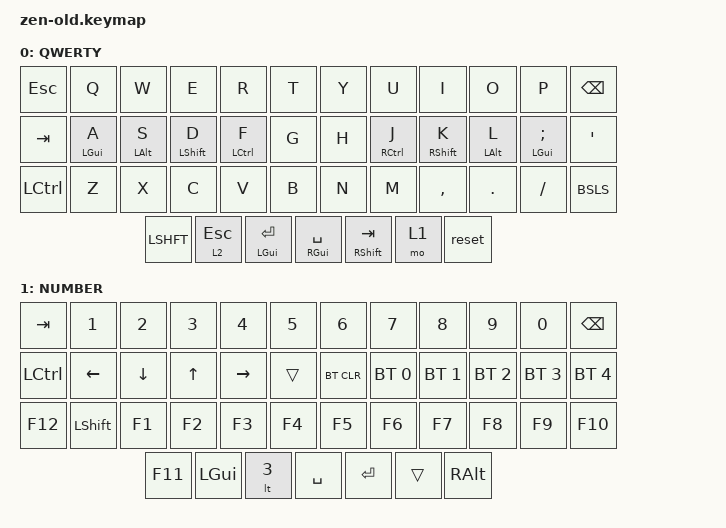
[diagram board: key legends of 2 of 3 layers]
/*
*
* Copyright (c) 2023 David Adams
*
*/

#include <behaviors.dtsi>
#include <dt-bindings/zmk/keys.h>
#include <dt-bindings/zmk/bt.h>


&mt {
    flavor = "hold-preferred";
    tapping-term-ms = <200>;
};

&lt {
    flavor = "balanced";
    tapping-term-ms = <190>;
};

/ {
    behaviors {
        am: alpha_mods {
            compatible = "zmk,behavior-hold-tap";
            label = "ALPHA_MT";
            #binding-cells = <2>;
            tapping-term-ms = <200>;
            quick-tap-ms = <150>;
            flavor = "tap-preferred";
            bindings = <&kp>, <&kp>;
        };
        as: alpha_shift {
            compatible = "zmk,behavior-hold-tap";
            label = "ALPHA_SFT";
            #binding-cells = <2>;
            tapping-term-ms = <200>;
            quick-tap-ms = <150>;
            flavor = "tap-preferred";
            bindings = <&kp>, <&kp>;
        };
    };
        keymap {
                compatible = "zmk,keymap";

                default_layer {
                        label = "QWERTY";
// -----------------------------------------------------------------------------------------
// |  TAB |  Q  |  W  |  E  |  R  |  T  |   |  Y  |  U   |  I  |  O  |  P  | BKSP |
// | CTRL |  A  |  S  |  D  |  F  |  G  |   |  H  |  J   |  K  |  L  |  ;  |  '   |
// | SHFT |  Z  |  X  |  C  |  V  |  B  |   |  N  |  M   |  ,  |  .  |  /  | ESC  |
//                    | GUI | LWR | ENT |   | SPC | RSE  | ALT |
                        bindings = <
   &kp ESC  &kp Q &kp W &kp E &kp R &kp T   &kp Y &kp U  &kp I     &kp O   &kp P    &kp BSPC
 &kp TAB &mt LGUI A &mt LALT S &mt LSHIFT D &mt LCTL F &kp G &kp H &mt RCTRL J &mt RSHFT K &mt LALT L &mt LGUI SEMI &kp SQT
 &kp LCTL &kp Z      &kp X      &kp C        &kp V      &kp B &kp N &kp M       &kp COMMA   &kp DOT    &kp FSLH      &kp BSLS
                LSHFT &lt 2 ESC &mt LGUI RET   &mt RGUI SPACE &mt RSHFT TAB &mo 1 &reset
                        >;
                };
                lower_layer {
                        label = "NUMBER";
// -----------------------------------------------------------------------------------------
// |  TAB |  1  |  2  |  3  |  4  |  5  |   |  6  |  7  |  8  |  9  |  0  | BKSP |
// | BTCLR| BT1 | BT2 | BT3 | BT4 | BT5 |   | LFT | DWN |  UP | RGT |     |      |
// | SHFT |     |     |     |     |     |   |     |     |     |     |     |      |
//                    | GUI |     | SPC |   | ENT |     | ALT |
                        bindings = <
   &kp TAB    &kp N1       &kp N2       &kp N3       &kp N4       &kp N5         &kp N6   &kp N7   &kp N8 &kp N9    &kp N0 &kp BSPC
   &kp LCTL   &kp LEFT &kp DOWN &kp UP &kp RIGHT &trans &bt BT_CLR &bt BT_SEL 0 &bt BT_SEL 1 &bt BT_SEL 2 &bt BT_SEL 3 &bt BT_SEL 4 &kp F12
   &kp LSHFT  &kp F1  &kp F2   &kp F3  &kp F4 &kp F5 &kp F6 &kp F7   &kp F8 &kp F9    &kp F10 &kp F11
                          	        &kp LGUI     &lt 3       &kp SPACE      &kp RET  &trans   &kp RALT
                        >;
                };

                raise_layer {
                        label = "SYMBOL";
// -----------------------------------------------------------------------------------------
// |  ~   |  !  |  @  |  #  |  $  |  %  |   |  ^  |  &  |  *  |  (  |  )  | BKSP |
// | CTRL | "|" |  \  |  =  |  -  |  (  |   |  )  |  =  |  [  |  ]  |  \  |  `   |
// | SHFT |  {  |  }  |  +  |  _  |  [  |   |  ]  |  +  |  {  |  }  | "|" |  ~   |
//                    | GUI |     | SPC |   | ENT |     | ALT |
                        bindings = <
   &kp  TAB  &kp EXCL &kp AT &kp HASH &kp DLLR &kp PRCNT   &kp CARET &kp AMPS  &kp KP_MULTIPLY &kp LPAR &kp RPAR &kp BSPC
   &kp LCTRL &kp PIPE   &kp BSLH &kp EQUAL   &kp MINUS   &kp LPAR      &kp RPAR &kp EQUAL &kp LBKT  &kp RBKT &kp BSLH &kp GRAVE
   &kp LSHFT &kp LBRC   &kp RBRC &kp PLUS   &kp UNDER   &kp LBRC      &kp RBRC &kp PLUS  &kp LBRC  &kp RBRC &kp PIPE &kp TILDE
                    	     &kp LGUI &trans   &kp SPACE   &kp RET   &trans    &kp RALT
                        >;
                };
        };
};

                        //label = "SYMBOL";
// -----------------------------------------------------------------------------------------
// |  ~   |  !  |  @  |  #  |  $  |  %  |   |  ^  |  &  |  *  |  (  |  )  | BKSP |
// | CTRL | "|" |  \  |  =  |  -  |  (  |   |  )  |  =  |  [  |  ]  |  \  |  `   |
// | SHFT |  {  |  }  |  +  |  _  |  [  |   |  ]  |  +  |  {  |  }  | "|" |  ~   |
//                    | GUI |     | SPC |   | ENT |     | ALT |
                        //bindings = <
   //&kp  TAB  &kp EXCL &kp AT &kp HASH &kp DLLR &kp PRCNT   &kp CARET &kp AMPS  &kp KP_MULTIPLY &kp LPAR &kp RPAR &kp BSPC
   //&kp LCTRL &kp PIPE   &kp BSLH &kp EQUAL   &kp MINUS   &LPAR      &kp RPAR &kp EQUAL &kp LBKT &kp RBKT &kp BSLH &kp GRAVE
   //&kp LSHFT &kp LBRC   &kp RBRC &kp PLUS   &kp UNDER   &kp LBKT      &kp RBKT &kp PLUS  &kp LBRC        &kp RBRC &kp PIPE &kp TILDE
                    	     //&kp LGUI &trans   &kp SPACE   &kp RET   &trans    &kp RALT
